# nrf9120_MLM1 register map
Vendor: Nordic Semiconductor; Series: nrf91; File version: 1
CPU: CM4 r0p1, little endian, MPU, FPU, 3 interrupt priority bits
Registers are 32-bit, read-write, reset 0x0 unless marked. A register's access mark holds for its fields unless they carry their own. Offsets are from the block's base; [hi:lo] are bit positions; {n}, {i} and the like mark numbered series; 'fields as' and 'values as' point back to an identical list.

## RTC0 — Real time counter 0
Base 0x4000F000
Same registers: RTC1 0x4001B000
0x00 TASKS_START wo — Start RTC COUNTER
0x04 TASKS_STOP wo — Stop RTC COUNTER
0x08 TASKS_CLEAR wo — Clear RTC COUNTER
0x0C TASKS_TRIGOVRFLW wo — Set COUNTER to 0xFFFFF0
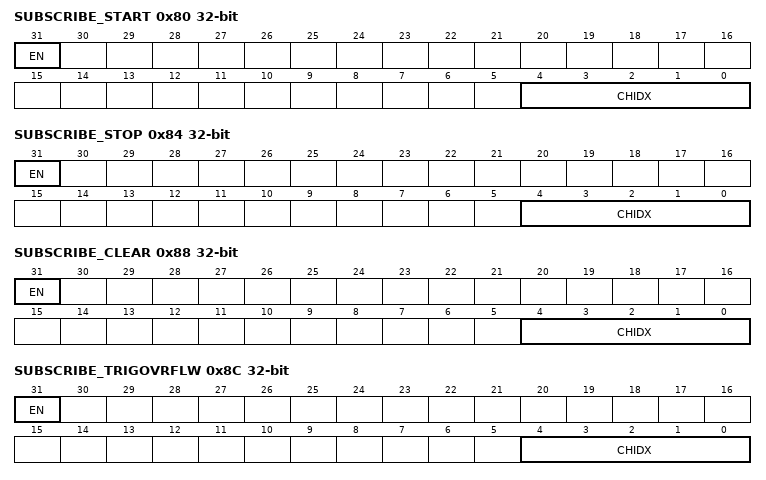
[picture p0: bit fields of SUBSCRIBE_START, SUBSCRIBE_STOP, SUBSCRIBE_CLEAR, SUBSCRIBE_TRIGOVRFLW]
0x80 SUBSCRIBE_START — Subscribe configuration for TASKS_START
  [31] EN
    0=Disabled (Disable subscription); 1=Enabled (Enable subscription)
  [4:0] CHIDX — Channel the TASKS_START will subscribe to.
0x84 SUBSCRIBE_STOP — Subscribe configuration for TASKS_STOP
  [31] EN
    values as SUBSCRIBE_START.EN
  [4:0] CHIDX — Channel the TASKS_STOP will subscribe to.
0x88 SUBSCRIBE_CLEAR — Subscribe configuration for TASKS_CLEAR
  [31] EN
    values as SUBSCRIBE_START.EN
  [4:0] CHIDX — Channel the TASKS_CLEAR will subscribe to.
0x8C SUBSCRIBE_TRIGOVRFLW — Subscribe configuration for TASKS_TRIGOVRFLW
  [31] EN
    values as SUBSCRIBE_START.EN
  [4:0] CHIDX — Channel the TASKS_TRIGOVRFLW will subscribe to.
0x100 EVENTS_TICK — Event on COUNTER increment
0x104 EVENTS_OVRFLW — Event on COUNTER overflow
{0x140+4i} EVENTS_COMPARE[{i}] (i=0..3) — Description collection[0]: Compare event on CC[0] match
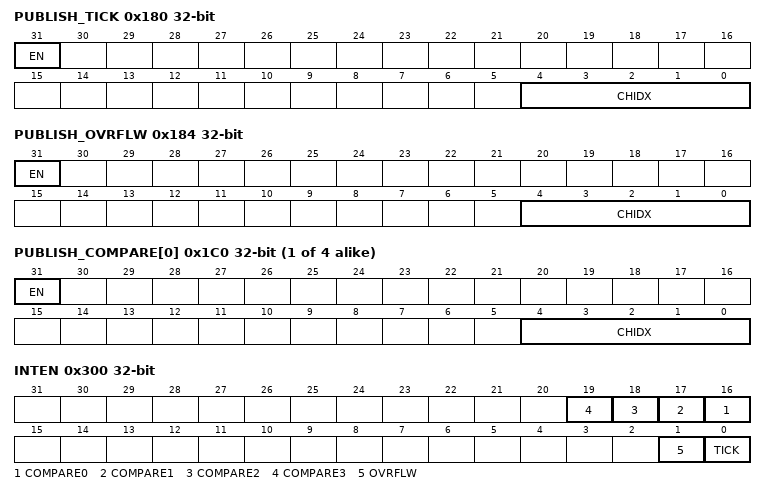
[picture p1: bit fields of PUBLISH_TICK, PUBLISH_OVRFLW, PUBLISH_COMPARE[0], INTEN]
0x180 PUBLISH_TICK — Publish configuration for EVENTS_TICK
  [31] EN
    0=Disabled (Disable publishing); 1=Enabled (Enable publishing)
  [4:0] CHIDX — Channel the EVENTS_TICK will subscribe to.
0x184 PUBLISH_OVRFLW — Publish configuration for EVENTS_OVRFLW
  [31] EN
    values as PUBLISH_TICK.EN
  [4:0] CHIDX — Channel the EVENTS_OVRFLW will subscribe to.
{0x1C0+4i} PUBLISH_COMPARE[{i}] (i=0..3) — Description collection[0]: Publish configuration for EVENTS_COMPARE[0]
  [31] EN
    values as PUBLISH_TICK.EN
  [4:0] CHIDX — Channel the EVENTS_COMPARE[0] will subscribe to.
0x300 INTEN — Enable or disable interrupt
  [all] fields
    0=Disabled; 1=Enabled
  [n+16] COMPARE{n} (n=0..3) — Enable or disable interrupt for COMPARE[{n}] event
  [1] OVRFLW — Enable or disable interrupt for OVRFLW event
  [0] TICK — Enable or disable interrupt for TICK event
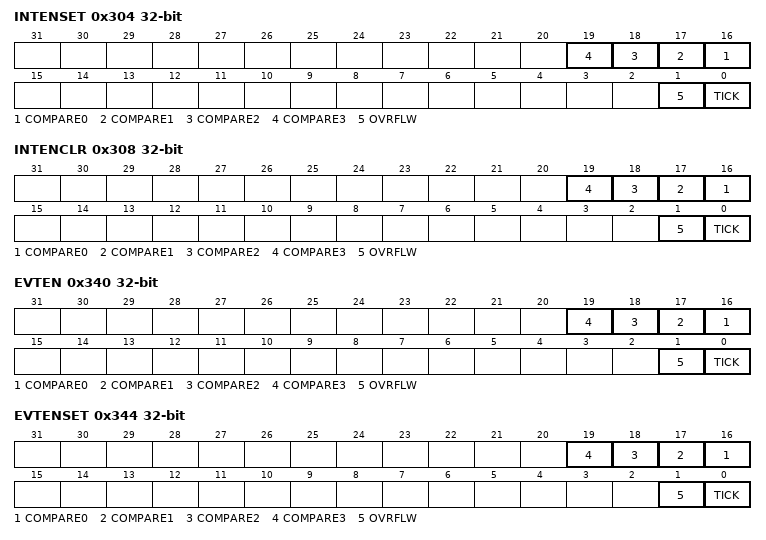
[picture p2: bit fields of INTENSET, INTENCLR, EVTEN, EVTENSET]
0x304 INTENSET — Enable interrupt
  [all] fields
    on read: 0=Disabled (Read: Disabled); 1=Enabled (Read: Enabled) | on write: 1=Set (Enable)
  [n+16] COMPARE{n} (n=0..3) — Write '1' to Enable interrupt for COMPARE[{n}] event
  [1] OVRFLW — Write '1' to Enable interrupt for OVRFLW event
  [0] TICK — Write '1' to Enable interrupt for TICK event
0x308 INTENCLR — Disable interrupt
  [all] fields
    on read: 0=Disabled (Read: Disabled); 1=Enabled (Read: Enabled) | on write: 1=Clear (Disable)
  [n+16] COMPARE{n} (n=0..3) — Write '1' to Disable interrupt for COMPARE[{n}] event
  [1] OVRFLW — Write '1' to Disable interrupt for OVRFLW event
  [0] TICK — Write '1' to Disable interrupt for TICK event
0x340 EVTEN — Enable or disable event routing
  [all] fields
    0=Disabled; 1=Enabled
  [n+16] COMPARE{n} (n=0..3) — Enable or disable event routing for COMPARE[{n}] event
  [1] OVRFLW — Enable or disable event routing for OVRFLW event
  [0] TICK — Enable or disable event routing for TICK event
0x344 EVTENSET — Enable event routing
  [all] fields
    values as the fields of INTENSET
  [n+16] COMPARE{n} (n=0..3) — Write '1' to Enable event routing for COMPARE[{n}] event
  [1] OVRFLW — Write '1' to Enable event routing for OVRFLW event
  [0] TICK — Write '1' to Enable event routing for TICK event
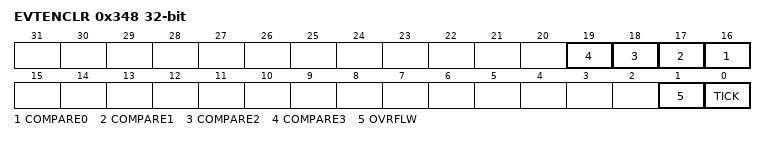
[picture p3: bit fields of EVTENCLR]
0x348 EVTENCLR — Disable event routing
  [all] fields
    values as the fields of INTENCLR
  [n+16] COMPARE{n} (n=0..3) — Write '1' to Disable event routing for COMPARE[{n}] event
  [1] OVRFLW — Write '1' to Disable event routing for OVRFLW event
  [0] TICK — Write '1' to Disable event routing for TICK event
0x504 COUNTER ro — Current COUNTER value
  [23:0] COUNTER — Counter value
0x508 PRESCALER — 12 bit prescaler for COUNTER frequency (32768/(PRESCALER+1)).Must be written when RTC is stopped
  [11:0] PRESCALER — Prescaler value
{0x540+4i} CC[{i}] (i=0..3) — Description collection[0]: Compare register 0
  [23:0] COMPARE — Compare value
0xFFC POWER reset 0x1 — Peripheral power control
  [0] POWER — Peripheral power control. The peripheral and its registers will be reset to its initial state by switching the peripheral off and then back on again.
    0=Disabled (Peripheral is powered off); 1=Enabled (Peripheral is powered on)
